# NUC100DN_v1 register map
File version: 1.0
Registers are 32-bit, read-write, reset 0x0 unless marked. A register's access mark holds for its fields unless they carry their own. Offsets are from the block's base; [hi:lo] are bit positions; lines under a group give offsets from that group; {n}, {i} and the like mark numbered series.

## NVIC — NVIC Register Map
Base 0xE000E000
0x100 NVIC_ISER — IRQ0 ~ IRQ31 Set-enable Control Register
  [31:0] SETENA — Interrupt Enable Register. Enable one or more interrupts within a group of 32. Each Bit Represents an Interrupt Number From IRQ0 ~ IRQ31 (Vector Number From 16 ~ 47). The register reads back with the current enable state.
    0=No effect; 1=Associated interrupt Enabled
0x180 NVIC_ICER — IRQ0 ~ IRQ31 Clear-enable Control Register
  [31:0] CLRENA — Interrupt Disable Bits. Disable one or more interrupts within a group of 32. Each Bit Represents an Interrupt Number From IRQ0 ~ IRQ31 (Vector Number From 16 ~ 47). The register reads back with the current enable state.
    0=No effect; 1=Associated interrupt Enabled
0x200 NVIC_ISPR — IRQ0 ~ IRQ31 Set-pending Control Register
  [31:0] SETPEND — Set Interrupt Pending Register. The register reads back with the current pending state.
    0=No effect; 1=Set pending state of the associated interrupt under software control. Each bit represents an interrupt number from IRQ0 ~ IRQ31 (Vector number from 16 ~ 47)
0x280 NVIC_ICPR — IRQ0 ~ IRQ31 Clear-pending Control Register
  [31:0] CLRPEND — Clear Interrupt Pending Register. The register reads back with the current pending state.
    0=No effect; 1=Remove the pending state of associated interrupt under software control. Each bit represents an interrupt number from IRQ0 ~ IRQ31 (Vector number from 16 ~ 47)
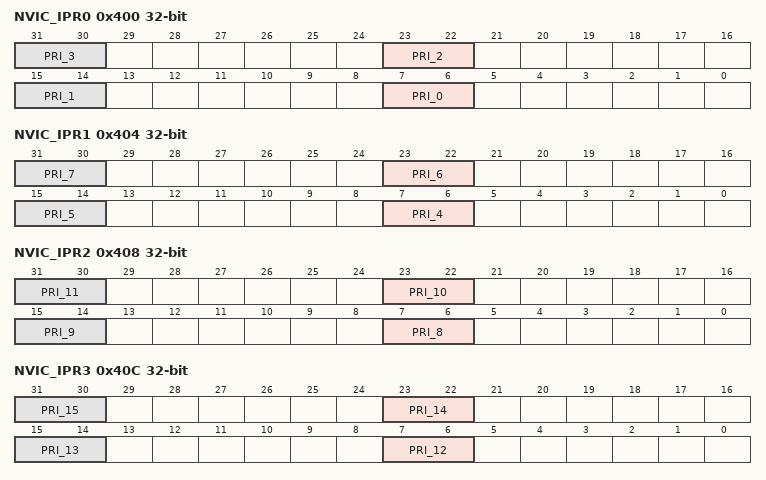
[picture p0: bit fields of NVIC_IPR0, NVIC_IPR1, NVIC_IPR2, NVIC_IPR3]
0x400 NVIC_IPR0 — IRQ0 ~ IRQ3 Priority Control Register
  [8n+7:8n+6] PRI_{n} (n=0..3) — Priority of IRQ{n} "0" denotes the highest priority and "3" denotes the lowest priority
0x404 NVIC_IPR1 — IRQ4 ~ IRQ7 Priority Control Register
  [8n-25:8n-26] PRI_{n} (n=4..7) — Priority of IRQ{n} "0" denotes the highest priority and "3" denotes the lowest priority
0x408 NVIC_IPR2 — IRQ8 ~ IRQ11 Priority Control Register
  [8n-57:8n-58] PRI_{n} (n=8..11) — Priority of IRQ{n} "0" denotes the highest priority and "3" denotes the lowest priority
0x40C NVIC_IPR3 — IRQ12 ~ IRQ15 Priority Control Register
  [8n-89:8n-90] PRI_{n} (n=12..15) — Priority of IRQ{n} "0" denotes the highest priority and "3" denotes the lowest priority
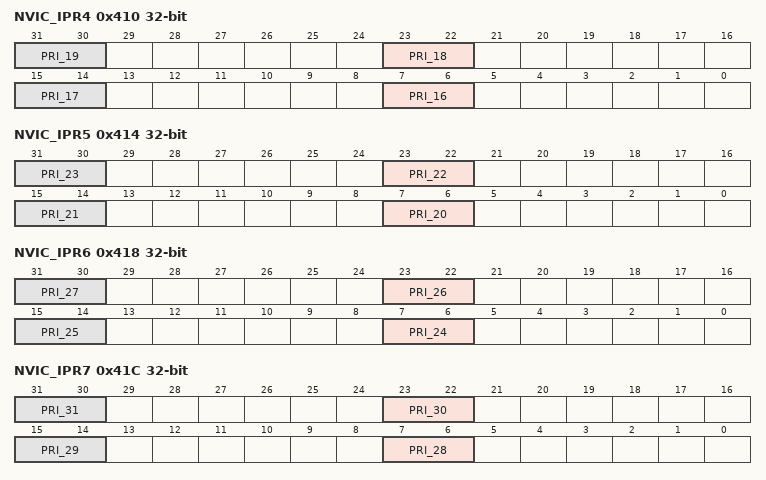
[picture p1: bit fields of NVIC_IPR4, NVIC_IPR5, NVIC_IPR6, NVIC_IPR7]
0x410 NVIC_IPR4 — IRQ16 ~ IRQ19 Priority Control Register
  [8n-121:8n-122] PRI_{n} (n=16..19) — Priority of IRQ{n} "0" denotes the highest priority and "3" denotes the lowest priority
0x414 NVIC_IPR5 — IRQ20 ~ IRQ23 Priority Control Register
  [8n-153:8n-154] PRI_{n} (n=20..23) — Priority of IRQ{n} "0" denotes the highest priority and "3" denotes the lowest priority
0x418 NVIC_IPR6 — IRQ24 ~ IRQ27 Priority Control Register
  [8n-185:8n-186] PRI_{n} (n=24..27) — Priority of IRQ{n} "0" denotes the highest priority and "3" denotes the lowest priority
0x41C NVIC_IPR7 — IRQ28 ~ IRQ31 Priority Control Register
  [8n-217:8n-218] PRI_{n} (n=28..31) — Priority of IRQ{n} "0" denotes the highest priority and "3" denotes the lowest priority

## EBI — EBI Register Map
Base 0x50010000
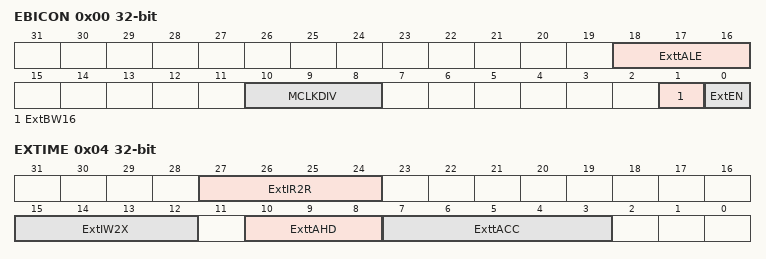
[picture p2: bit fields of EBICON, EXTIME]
0x00 EBICON — External Bus Interface General Control Register
  [18:16] ExttALE — Expand Time of ALE. This field is used for control the ALE pulse width (tALE) for latch the address
  [10:8] MCLKDIV — External Output Clock Divider. The frequency of EBI output clock (MCLK) is controlled by MCLKDIV as shown below. Note: Default value of output clock is HCLK/1
    0=HCLK/1; 1=HCLK/2; 2=HCLK/4; 3=HCLK/8; 4=HCLK/16; 5=HCLK/32; 6=Default; 7=Default
  [1] ExtBW16 — EBI Data Width 16-bit/8-bit. This bit defines if the data bus is 8-bit or 16-bit.
    0=EBI data width is 8-bit; 1=EBI data width is 16-bit
  [0] ExtEN — EBI Enable Bit. This bit is the functional enable bit for EBI.
    0=EBI function Disabled; 1=EBI function Enabled
0x04 EXTIME — External Bus Interface Timing Control Register
  [27:24] ExtIR2R — Idle State Cycle Between Read-read. When read action is finished and the next action is going to read, idle state is inserted and nCS signal return to high if ExtIR2R is not zero.
  [15:12] ExtIW2X — Idle State Cycle After Write. When write action is finished, idle state is inserted and nCS signal return to high if ExtIW2X is not zero.
  [10:8] ExttAHD — EBI Data Access Hold Time. ExttAHD defines data access hold time (tAHD).
  [7:3] ExttACC — EBI Data Access Time. ExttACC defines data access time (tACC).
